VERSION ""

NS_ :

BS_:

BU_: ADAS

BO_ 3221225472 VECTOR__INDEPENDENT_SIG_MSG: 0 Vector__XXX
 SG_ AdsBcuExtAebCtlIfErr : 0|1@1+ (1,0) [0|1] "" Vector__XXX
 SG_ AdsBcuErr : 0|1@1+ (1,0) [0|1] "" Vector__XXX
 SG_ AdsAebHmiErr : 0|1@1+ (1,0) [0|1] "" Vector__XXX
 SG_ AdsSplyUErr : 0|1@1+ (1,0) [0|1] "" Vector__XXX
 SG_ AdsCurvErr : 0|1@1+ (1,0) [0|1] "" Vector__XXX
 SG_ AdsVLgtErr : 0|1@1+ (1,0) [0|1] "" Vector__XXX
 SG_ AdsHmiErr : 0|1@1+ (1,0) [0|1] "" Vector__XXX
 SG_ AdsAccrPedlPosnErr : 0|1@1+ (1,0) [0|1] "" Vector__XXX
 SG_ AdsGearPosnErr : 0|1@1+ (1,0) [0|1] "" Vector__XXX
 SG_ AdsAebErr : 0|1@1+ (1,0) [0|1] "" Vector__XXX
 SG_ AdsWhlSpdErr : 0|1@1+ (1,0) [0|1] "" Vector__XXX
 SG_ AdsYawRateErr : 0|1@1+ (1,0) [0|1] "" Vector__XXX
 SG_ AdsAccLatErr : 0|1@1+ (1,0) [0|1] "" Vector__XXX
 SG_ AdsAccLgtErr : 0|1@1+ (1,0) [0|1] "" Vector__XXX
 SG_ AdsBrkPedlPosnErr : 0|1@1+ (1,0) [0|1] "" Vector__XXX
 SG_ AdsRoadWhlAgErr : 0|1@1+ (1,0) [0|1] "" Vector__XXX
 SG_ AdsRadarErr : 0|1@1+ (1,0) [0|1] "" Vector__XXX
 SG_ AdsDriverTqReqErr : 0|1@1+ (1,0) [0|1] "" Vector__XXX
 SG_ AdsRadarBlkg : 0|1@1+ (1,0) [0|1] "" Vector__XXX

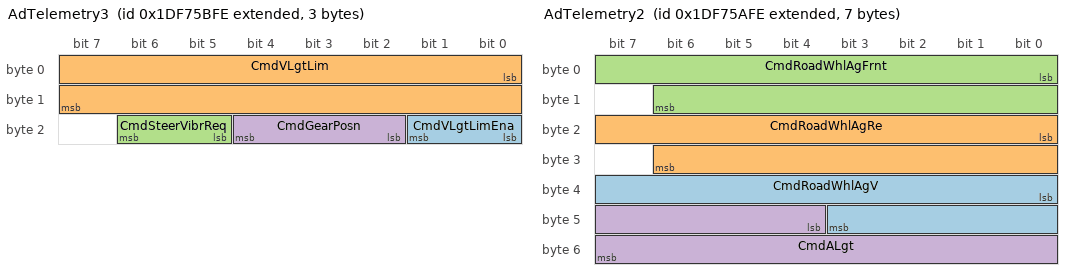
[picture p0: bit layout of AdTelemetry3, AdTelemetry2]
BO_ 2650233854 AdTelemetry3: 3 Vector__XXX
 SG_ CmdVLgtLimEna : 16|2@1+ (1,0) [0|3] "" Vector__XXX
 SG_ CmdVLgtLim : 0|16@1- (0.01,0) [-327.68|327.67] "m/s" Vector__XXX
 SG_ CmdSteerVibrReq : 21|2@1+ (1,0) [0|3] "" Vector__XXX
 SG_ CmdGearPosn : 18|3@1+ (1,0) [0|7] "" Vector__XXX

BO_ 2650233598 AdTelemetry2: 7 Vector__XXX
 SG_ CmdRoadWhlAgV : 32|12@1+ (0.01,0) [-20.48|20.47] "rad/s" Vector__XXX
 SG_ CmdRoadWhlAgRe : 16|15@1- (0.0001,0) [-1.6384|1.6383] "rad" Vector__XXX
 SG_ CmdRoadWhlAgFrnt : 0|15@1- (0.0001,0) [-1.6384|1.6383] "rad" Vector__XXX
 SG_ CmdALgt : 44|12@1- (0.01,0) [-20.48|20.47] "m/s^2" Vector__XXX

BO_ 2650233342 AdTelemetry1: 5 Vector__XXX
 SG_ CmdLgtExtReqPri : 30|2@1+ (1,0) [0|3] "" Vector__XXX
 SG_ CmdLgtExtReqMod : 27|3@1+ (1,0) [0|7] "" Vector__XXX
 SG_ CmdLatExtReqPri : 35|2@1+ (1,0) [0|3] "" Vector__XXX
 SG_ CmdLatExtReqMod : 32|3@1+ (1,0) [0|7] "" Vector__XXX
 SG_ AdSftyMod : 8|3@1+ (1,0) [0|7] "" Vector__XXX
 SG_ AdSteerTkvr : 4|1@1+ (1,0) [0|1] "" Vector__XXX
 SG_ AdSteerAcv : 1|1@1+ (1,0) [0|1] "" Vector__XXX
 SG_ AdSt : 11|3@1+ (1,0) [0|7] "" Vector__XXX
 SG_ AdHmiSt : 14|2@1+ (1,0) [0|3] "" Vector__XXX
 SG_ AdHmiEna : 16|3@1+ (1,0) [0|7] "" Vector__XXX
 SG_ AdDtTkvr : 5|1@1+ (1,0) [0|1] "" Vector__XXX
 SG_ AdDtAcv : 2|1@1+ (1,0) [0|1] "" Vector__XXX
 SG_ AdCtlMod : 19|3@1+ (1,0) [0|7] "" Vector__XXX
 SG_ AdCommSt : 22|2@1+ (1,0) [0|3] "" Vector__XXX
 SG_ AdCommEna : 24|3@1+ (1,0) [0|7] "" Vector__XXX
 SG_ AdBrkTkvr : 6|1@1+ (1,0) [0|1] "" Vector__XXX
 SG_ AdBrkAcv : 3|1@1+ (1,0) [0|1] "" Vector__XXX
 SG_ AdAcv : 0|1@1+ (1,0) [0|1] "" Vector__XXX

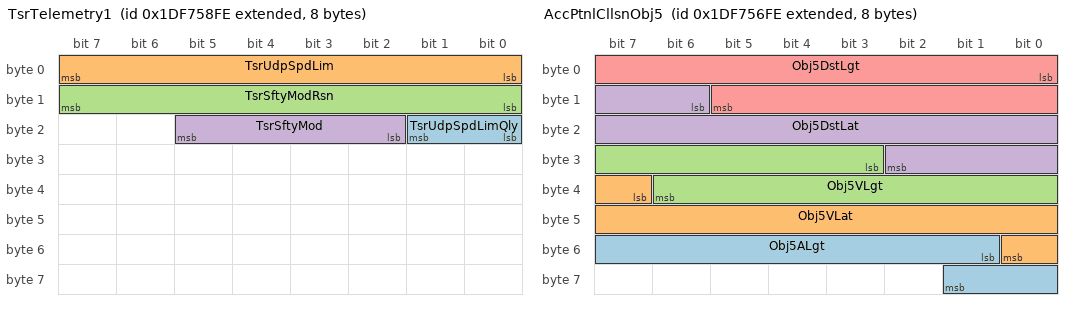
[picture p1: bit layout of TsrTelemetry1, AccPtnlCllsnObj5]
BO_ 2650233086 TsrTelemetry1: 8 Vector__XXX
 SG_ TsrUdpSpdLimQly : 16|2@1+ (1,0) [0|3] "" Vector__XXX
 SG_ TsrUdpSpdLim : 0|8@1+ (1,0) [0|255] "km/h" Vector__XXX
 SG_ TsrSftyModRsn : 8|8@1+ (1,0) [0|255] "" Vector__XXX
 SG_ TsrSftyMod : 18|4@1+ (1,0) [0|15] "" Vector__XXX

BO_ 2650232830 AebTelemetry2: 8 Vector__XXX
 SG_ AebSftyModRsn : 0|32@1+ (1,0) [0|4294967295] "" Vector__XXX

BO_ 2650232574 AccPtnlCllsnObj5: 8 Vector__XXX
 SG_ Obj5ALgt : 49|9@1+ (0.05,-12.8) [-12.8|12.75] "m/s^2" Vector__XXX
 SG_ Obj5VLat : 39|10@1+ (0.05,-25.6) [-25.6|25.55] "m/s" Vector__XXX
 SG_ Obj5VLgt : 27|12@1+ (0.05,-102.4) [-102.4|102.35] "m/s" Vector__XXX
 SG_ Obj5DstLat : 14|13@1+ (0.02,-81.92) [-81.92|81.9] "m" Vector__XXX
 SG_ Obj5DstLgt : 0|14@1+ (0.02,0) [0|327.66] "m" Vector__XXX

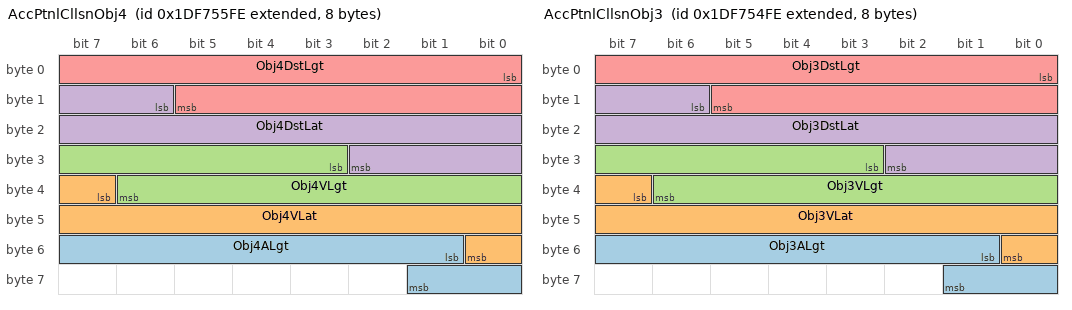
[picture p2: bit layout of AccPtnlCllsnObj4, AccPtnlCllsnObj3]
BO_ 2650232318 AccPtnlCllsnObj4: 8 Vector__XXX
 SG_ Obj4ALgt : 49|9@1+ (0.05,-12.8) [-12.8|12.75] "m/s^2" Vector__XXX
 SG_ Obj4VLat : 39|10@1+ (0.05,-25.6) [-25.6|25.55] "m/s" Vector__XXX
 SG_ Obj4VLgt : 27|12@1+ (0.05,-102.4) [-102.4|102.35] "m/s" Vector__XXX
 SG_ Obj4DstLat : 14|13@1+ (0.02,-81.92) [-81.92|81.9] "m" Vector__XXX
 SG_ Obj4DstLgt : 0|14@1+ (0.02,0) [0|327.66] "m" Vector__XXX

BO_ 2650232062 AccPtnlCllsnObj3: 8 Vector__XXX
 SG_ Obj3ALgt : 49|9@1+ (0.05,-12.8) [-12.8|12.75] "m/s^2" Vector__XXX
 SG_ Obj3VLat : 39|10@1+ (0.05,-25.6) [-25.6|25.55] "m/s" Vector__XXX
 SG_ Obj3VLgt : 27|12@1+ (0.05,-102.4) [-102.4|102.35] "m/s" Vector__XXX
 SG_ Obj3DstLat : 14|13@1+ (0.02,-81.92) [-81.92|81.9] "m" Vector__XXX
 SG_ Obj3DstLgt : 0|14@1+ (0.02,0) [0|327.66] "m" Vector__XXX

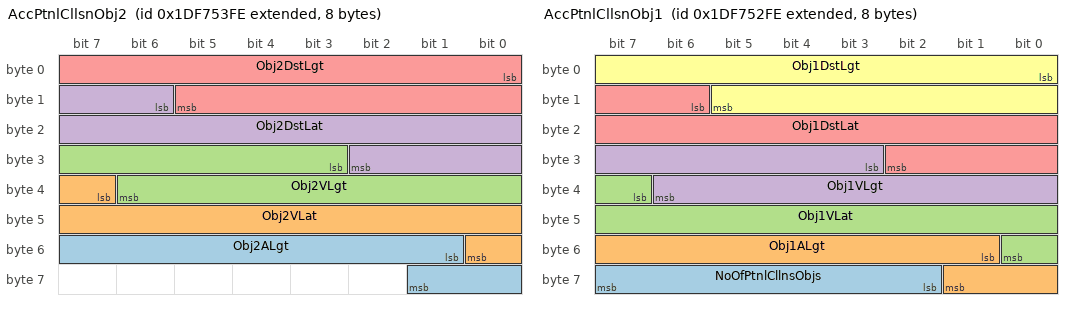
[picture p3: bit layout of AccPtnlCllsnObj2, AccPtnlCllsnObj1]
BO_ 2650231806 AccPtnlCllsnObj2: 8 Vector__XXX
 SG_ Obj2ALgt : 49|9@1+ (0.05,-12.8) [-12.8|12.75] "m/s^2" Vector__XXX
 SG_ Obj2VLat : 39|10@1+ (0.05,-25.6) [-25.6|25.55] "m/s" Vector__XXX
 SG_ Obj2VLgt : 27|12@1+ (0.05,-102.4) [-102.4|102.35] "m/s" Vector__XXX
 SG_ Obj2DstLat : 14|13@1+ (0.02,-81.92) [-81.92|81.9] "m" Vector__XXX
 SG_ Obj2DstLgt : 0|14@1+ (0.02,0) [0|327.66] "m" Vector__XXX

BO_ 2650231550 AccPtnlCllsnObj1: 8 Vector__XXX
 SG_ NoOfPtnlCllnsObjs : 58|6@1+ (1,0) [0|63] "" Vector__XXX
 SG_ Obj1ALgt : 49|9@1+ (0.05,-12.8) [-12.8|12.75] "m/s^2" Vector__XXX
 SG_ Obj1VLat : 39|10@1+ (0.05,-25.6) [-25.6|25.55] "m/s" Vector__XXX
 SG_ Obj1VLgt : 27|12@1+ (0.05,-102.4) [-102.4|102.35] "m/s" Vector__XXX
 SG_ Obj1DstLat : 14|13@1+ (0.02,-81.92) [-81.92|81.9] "m" Vector__XXX
 SG_ Obj1DstLgt : 0|14@1+ (0.02,0) [0|327.66] "m" Vector__XXX

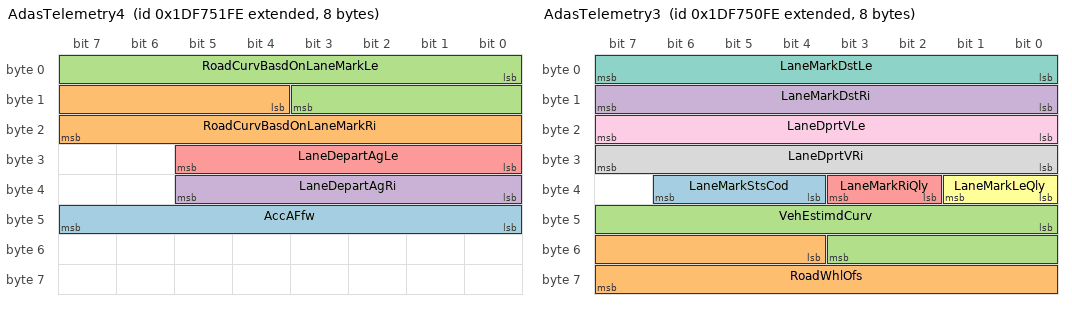
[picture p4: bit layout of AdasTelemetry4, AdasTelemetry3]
BO_ 2650231294 AdasTelemetry4: 8 Vector__XXX
 SG_ AccAFfw : 40|8@1+ (-0.01961,0) [-5.00055|0] "m/s^2" Vector__XXX
 SG_ RoadCurvBasdOnLaneMarkRi : 12|12@1+ (0.001,-2.048) [-2.048|2.047] "1/m" Vector__XXX
 SG_ RoadCurvBasdOnLaneMarkLe : 0|12@1+ (0.001,-2.048) [-2.048|2.047] "1/m" Vector__XXX
 SG_ LaneDepartAgRi : 32|6@1+ (0.01,-0.32) [-0.32|0.31] "rad" Vector__XXX
 SG_ LaneDepartAgLe : 24|6@1+ (0.01,-0.32) [-0.32|0.31] "rad" Vector__XXX

BO_ 2650231038 AdasTelemetry3: 8 Vector__XXX
 SG_ LaneMarkStsCod : 36|3@1+ (1,0) [0|7] "" Vector__XXX
 SG_ RoadWhlOfs : 52|12@1+ (1.7046E-005,-0.034901685) [-0.034901685|0.034901685] "rad" Vector__XXX
 SG_ VehEstimdCurv : 40|12@1+ (0.00048844,-1.0000809) [-1.0000809|1.0000809] "1/m" Vector__XXX
 SG_ LaneMarkDstRi : 8|8@1+ (0.02,0) [0|5.1] "m" Vector__XXX
 SG_ LaneMarkRiQly : 34|2@1+ (1,0) [0|3] "" Vector__XXX
 SG_ LaneMarkLeQly : 32|2@1+ (1,0) [0|3] "" Vector__XXX
 SG_ LaneMarkDstLe : 0|8@1+ (0.02,0) [0|5.1] "m" Vector__XXX
 SG_ LaneDprtVRi : 24|8@1+ (0.1,-12.8) [-12.8|12.7] "m/s" Vector__XXX
 SG_ LaneDprtVLe : 16|8@1+ (0.1,-12.8) [-12.8|12.7] "m/s" Vector__XXX

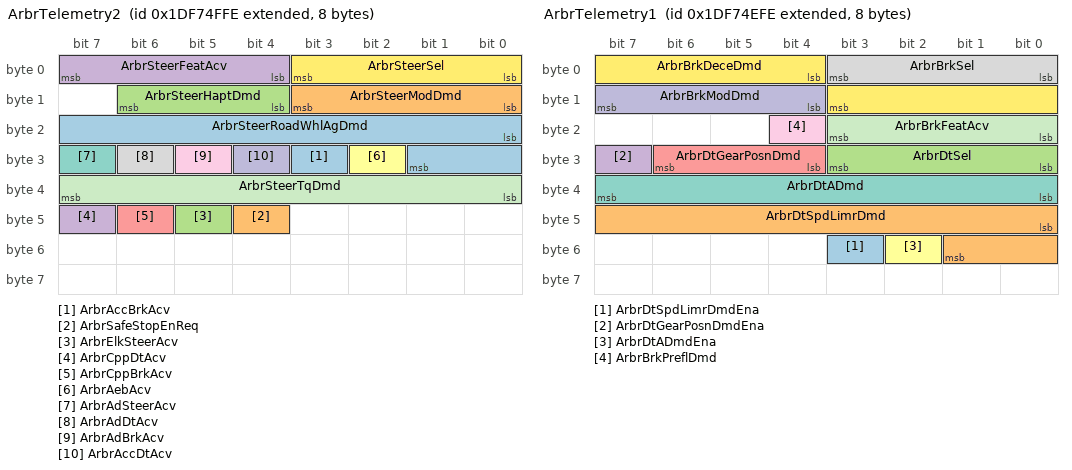
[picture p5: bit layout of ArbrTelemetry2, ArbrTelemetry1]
BO_ 2650230782 ArbrTelemetry2: 8 Vector__XXX
 SG_ ArbrAccBrkAcv : 27|1@1+ (1,0) [0|1] "" Vector__XXX
 SG_ ArbrSafeStopEnReq : 44|1@1+ (1,0) [0|1] "" Vector__XXX
 SG_ ArbrElkSteerAcv : 45|1@1+ (1,0) [0|1] "" Vector__XXX
 SG_ ArbrCppDtAcv : 47|1@1+ (1,0) [0|1] "" Vector__XXX
 SG_ ArbrCppBrkAcv : 46|1@1+ (1,0) [0|1] "" Vector__XXX
 SG_ ArbrAebAcv : 26|1@1+ (1,0) [0|1] "" Vector__XXX
 SG_ ArbrAdSteerAcv : 31|1@1+ (1,0) [0|1] "" Vector__XXX
 SG_ ArbrAdDtAcv : 30|1@1+ (1,0) [0|1] "" Vector__XXX
 SG_ ArbrAdBrkAcv : 29|1@1+ (1,0) [0|1] "" Vector__XXX
 SG_ ArbrAccDtAcv : 28|1@1+ (1,0) [0|1] "" Vector__XXX
 SG_ ArbrSteerTqDmd : 32|8@1+ (0.1,-12.8) [-12.8|12.7] "Nm" Vector__XXX
 SG_ ArbrSteerSel : 0|4@1+ (1,0) [0|15] "" Vector__XXX
 SG_ ArbrSteerRoadWhlAgDmd : 16|10@1+ (0.002,-1.024) [-1.024|1.022] "rad" Vector__XXX
 SG_ ArbrSteerModDmd : 8|4@1+ (1,0) [0|15] "" Vector__XXX
 SG_ ArbrSteerHaptDmd : 12|3@1+ (1,0) [0|7] "" Vector__XXX
 SG_ ArbrSteerFeatAcv : 4|4@1+ (1,0) [0|15] "" Vector__XXX

BO_ 2650230526 ArbrTelemetry1: 8 Vector__XXX
 SG_ ArbrDtSpdLimrDmdEna : 51|1@1+ (1,0) [0|1] "" Vector__XXX
 SG_ ArbrDtSpdLimrDmd : 40|10@1+ (0.05,0) [0|51.15] "m/s" Vector__XXX
 SG_ ArbrDtSel : 24|4@1+ (1,0) [0|15] "" Vector__XXX
 SG_ ArbrDtGearPosnDmdEna : 31|1@1+ (1,0) [0|1] "" Vector__XXX
 SG_ ArbrDtGearPosnDmd : 28|3@1+ (1,0) [0|7] "" Vector__XXX
 SG_ ArbrDtADmdEna : 50|1@1+ (1,0) [0|1] "" Vector__XXX
 SG_ ArbrDtADmd : 32|8@1+ (0.1,0) [0|25.5] "m/s^2" Vector__XXX
 SG_ ArbrBrkSel : 0|4@1+ (1,0) [0|15] "" Vector__XXX
 SG_ ArbrBrkPreflDmd : 20|1@1+ (1,0) [0|1] "" Vector__XXX
 SG_ ArbrBrkModDmd : 12|4@1+ (1,0) [0|15] "" Vector__XXX
 SG_ ArbrBrkFeatAcv : 16|4@1+ (1,0) [0|15] "" Vector__XXX
 SG_ ArbrBrkDeceDmd : 4|8@1+ (0.1,0) [0|25.5] "" Vector__XXX

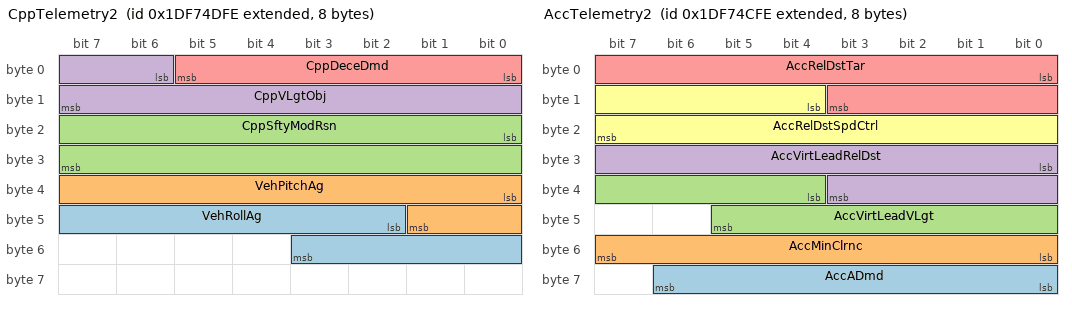
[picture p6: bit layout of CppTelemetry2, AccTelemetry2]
BO_ 2650230270 CppTelemetry2: 8 Vector__XXX
 SG_ VehRollAg : 42|10@1+ (0.05,-25.5) [-25.5|25.65] "deg" Vector__XXX
 SG_ VehPitchAg : 32|10@1+ (0.05,-25.5) [-25.5|25.65] "deg" Vector__XXX
 SG_ CppSftyModRsn : 16|16@1+ (1,0) [0|65535] "" Vector__XXX
 SG_ CppVLgtObj : 6|10@1+ (0.01,-5.12) [-5.12|5.11] "m/s" Vector__XXX
 SG_ CppDeceDmd : 0|6@1+ (0.1,0) [0|6.3] "m/s^2" Vector__XXX

BO_ 2650230014 AccTelemetry2: 8 Vector__XXX
 SG_ AccADmd : 56|7@1+ (0.1,-6.3) [-6.3|6.4] "m/s^2" Vector__XXX
 SG_ AccMinClrnc : 48|8@1+ (0.05,0) [0|12.75] "m" Vector__XXX
 SG_ AccVirtLeadVLgt : 36|10@1+ (0.05,0) [0|51.15] "m/s" Vector__XXX
 SG_ AccVirtLeadRelDst : 24|12@1+ (0.05,0) [0|204.75] "m" Vector__XXX
 SG_ AccRelDstTar : 0|12@1+ (0.05,0) [0|204.75] "m" Vector__XXX
 SG_ AccRelDstSpdCtrl : 12|12@1+ (0.05,0) [0|204.75] "m" Vector__XXX

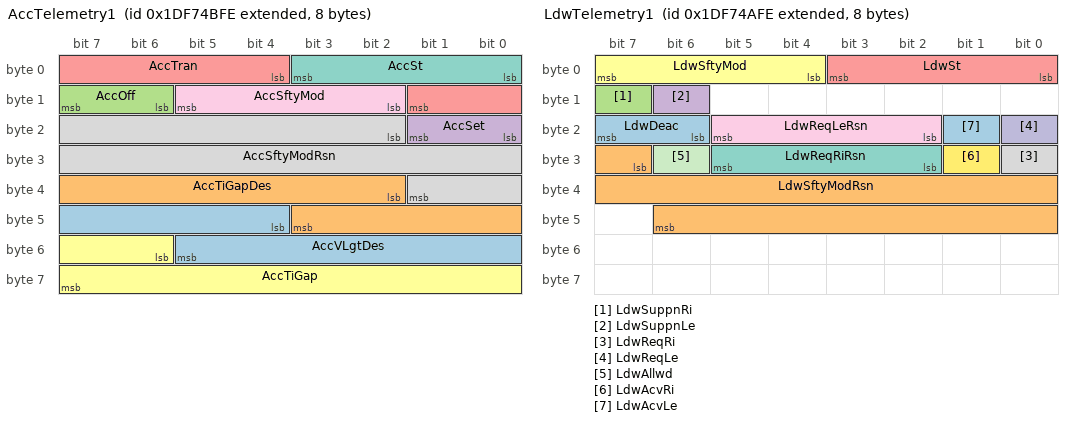
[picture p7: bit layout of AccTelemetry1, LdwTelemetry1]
BO_ 2650229758 AccTelemetry1: 8 Vector__XXX
 SG_ AccVLgtDes : 44|10@1+ (0.05,0) [0|51.15] "m/s" Vector__XXX
 SG_ AccTiGapDes : 34|10@1+ (0.01,0) [0|10.23] "s" Vector__XXX
 SG_ AccOff : 14|2@1+ (1,0) [0|3] "" Vector__XXX
 SG_ AccSet : 16|2@1+ (1,0) [0|3] "" Vector__XXX
 SG_ AccTran : 4|6@1+ (1,0) [0|63] "" Vector__XXX
 SG_ AccTiGap : 54|10@1+ (0.01,0) [0|10.23] "s" Vector__XXX
 SG_ AccSt : 0|4@1+ (1,0) [0|15] "" Vector__XXX
 SG_ AccSftyModRsn : 18|16@1+ (1,0) [0|65535] "" Vector__XXX
 SG_ AccSftyMod : 10|4@1+ (1,0) [0|15] "" Vector__XXX

BO_ 2650229502 LdwTelemetry1: 8 Vector__XXX
 SG_ LdwDeac : 22|2@1+ (1,0) [0|3] "" Vector__XXX
 SG_ LdwSftyModRsn : 31|16@1+ (1,0) [0|65535] "" Vector__XXX
 SG_ LdwSuppnRi : 15|1@1+ (1,0) [0|1] "" Vector__XXX
 SG_ LdwSuppnLe : 14|1@1+ (1,0) [0|1] "" Vector__XXX
 SG_ LdwSt : 0|4@1+ (1,0) [0|15] "" Vector__XXX
 SG_ LdwSftyMod : 4|4@1+ (1,0) [0|15] "" Vector__XXX
 SG_ LdwReqRiRsn : 26|4@1+ (1,0) [0|15] "" Vector__XXX
 SG_ LdwReqRi : 24|1@1+ (1,0) [0|1] "" Vector__XXX
 SG_ LdwReqLeRsn : 18|4@1+ (1,0) [0|15] "" Vector__XXX
 SG_ LdwReqLe : 16|1@1+ (1,0) [0|1] "" Vector__XXX
 SG_ LdwAllwd : 30|1@1+ (1,0) [0|1] "" Vector__XXX
 SG_ LdwAcvRi : 25|1@1+ (1,0) [0|1] "" Vector__XXX
 SG_ LdwAcvLe : 17|1@1+ (1,0) [0|1] "" Vector__XXX

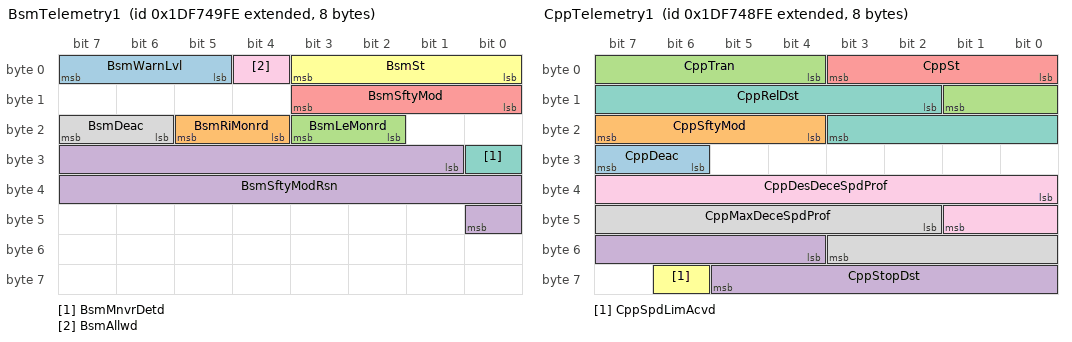
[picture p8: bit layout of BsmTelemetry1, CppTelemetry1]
BO_ 2650229246 BsmTelemetry1: 8 Vector__XXX
 SG_ BsmWarnLvl : 5|3@1+ (1,0) [0|7] "" Vector__XXX
 SG_ BsmRiMonrd : 20|2@1+ (1,0) [0|3] "" Vector__XXX
 SG_ BsmLeMonrd : 18|2@1+ (1,0) [0|3] "" Vector__XXX
 SG_ BsmSftyModRsn : 25|16@1+ (1,0) [0|65535] "" Vector__XXX
 SG_ BsmSftyMod : 8|4@1+ (1,0) [0|15] "" Vector__XXX
 SG_ BsmSt : 0|4@1+ (1,0) [0|15] "" Vector__XXX
 SG_ BsmMnvrDetd : 24|1@1+ (1,0) [0|1] "" Vector__XXX
 SG_ BsmDeac : 22|2@1+ (1,0) [0|3] "" Vector__XXX
 SG_ BsmAllwd : 4|1@1+ (1,0) [0|1] "" Vector__XXX

BO_ 2650228990 CppTelemetry1: 8 Vector__XXX
 SG_ CppDeac : 30|2@1+ (1,0) [0|3] "" Vector__XXX
 SG_ CppSftyMod : 20|4@1+ (1,0) [0|15] "" Vector__XXX
 SG_ CppTran : 4|6@1+ (1,0) [0|63] "" Vector__XXX
 SG_ CppStopDst : 52|10@1+ (0.01,-5.11) [-5.11|5.12] "m" Vector__XXX
 SG_ CppSt : 0|4@1+ (1,0) [0|15] "" Vector__XXX
 SG_ CppSpdLimAcvd : 62|1@1+ (1,0) [0|1] "" Vector__XXX
 SG_ CppRelDst : 10|10@1+ (0.01,-1) [-1|9.23] "m" Vector__XXX
 SG_ CppMaxDeceSpdProf : 42|10@1+ (0.01,0) [0|10.23] "m/s" Vector__XXX
 SG_ CppDesDeceSpdProf : 32|10@1+ (0.01,0) [0|10.23] "m/s" Vector__XXX

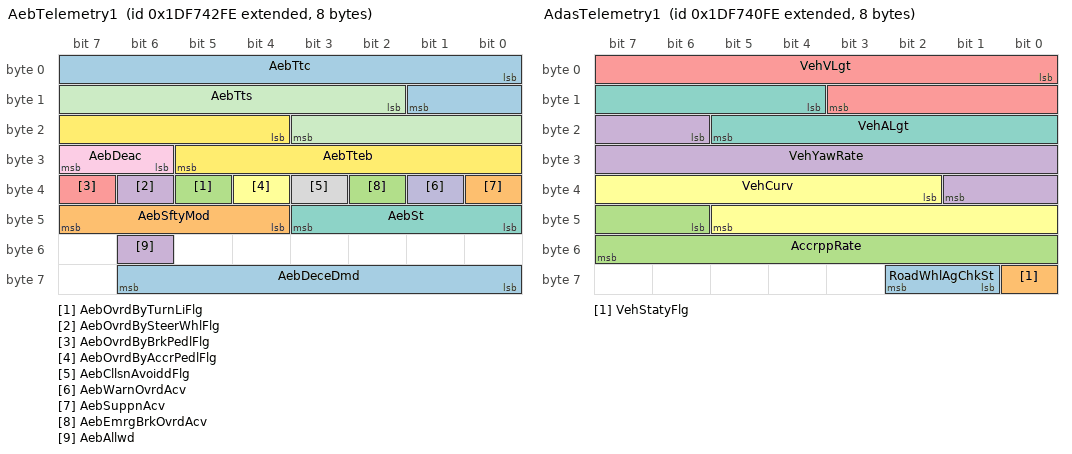
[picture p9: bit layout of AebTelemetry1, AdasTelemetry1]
BO_ 2650227454 AebTelemetry1: 8 Vector__XXX
 SG_ AebDeceDmd : 56|7@1+ (0.1,0) [0|12.7] "m/s^2" Vector__XXX
 SG_ AebSftyMod : 44|4@1+ (1,0) [0|15] "" Vector__XXX
 SG_ AebOvrdByTurnLiFlg : 37|1@1+ (1,0) [0|1] "" Vector__XXX
 SG_ AebOvrdBySteerWhlFlg : 38|1@1+ (1,0) [0|1] "" Vector__XXX
 SG_ AebOvrdByBrkPedlFlg : 39|1@1+ (1,0) [0|1] "" Vector__XXX
 SG_ AebOvrdByAccrPedlFlg : 36|1@1+ (1,0) [0|1] "" Vector__XXX
 SG_ AebSt : 40|4@1+ (1,0) [0|15] "" Vector__XXX
 SG_ AebCllsnAvoiddFlg : 35|1@1+ (1,0) [0|1] "" Vector__XXX
 SG_ AebDeac : 30|2@1+ (1,0) [0|3] "" Vector__XXX
 SG_ AebWarnOvrdAcv : 33|1@1+ (1,0) [0|1] "" Vector__XXX
 SG_ AebTts : 10|10@1+ (0.01,0) [0|10.23] "s" Vector__XXX
 SG_ AebTteb : 20|10@1+ (0.01,0) [0|10.23] "s" Vector__XXX
 SG_ AebTtc : 0|10@1+ (0.01,0) [0|10.23] "s" Vector__XXX
 SG_ AebSuppnAcv : 32|1@1+ (1,0) [0|1] "" Vector__XXX
 SG_ AebEmrgBrkOvrdAcv : 34|1@1+ (1,0) [0|1] "" Vector__XXX
 SG_ AebAllwd : 54|1@1+ (1,0) [0|1] "" Vector__XXX

BO_ 2650226942 AdasTelemetry1: 8 Vector__XXX
 SG_ RoadWhlAgChkSt : 57|2@1+ (1,0) [0|3] "" Vector__XXX
 SG_ VehStatyFlg : 56|1@1+ (1,0) [0|1] "" Vector__XXX
 SG_ AccrppRate : 46|10@1+ (2,-1024) [-1024|1022] "%/s" Vector__XXX
 SG_ VehYawRate : 22|12@1+ (0.001,-2.048) [-2.048|2.047] "rad/s" Vector__XXX
 SG_ VehVLgt : 0|12@1+ (0.05,-102.4) [-102.4|102.35] "m/s" Vector__XXX
 SG_ VehCurv : 34|12@1+ (0.00048844,-1.0000809) [-1.0000809|1.0000809] "1/m" Vector__XXX
 SG_ VehALgt : 12|10@1+ (0.05,-25.6) [-25.6|25.55] "m/s^2" Vector__XXX

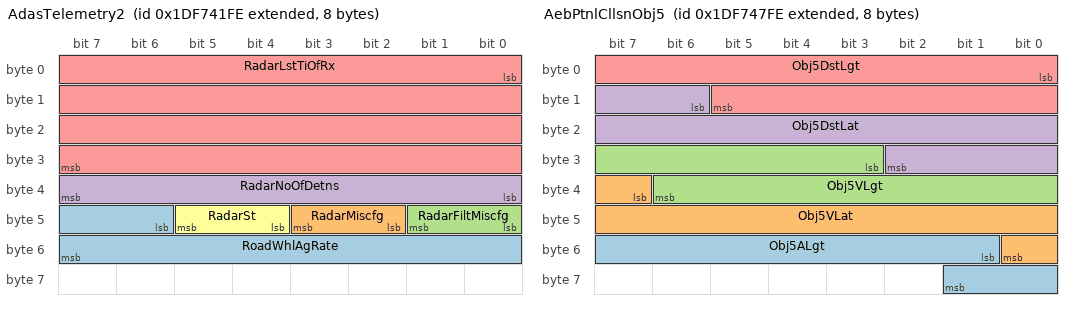
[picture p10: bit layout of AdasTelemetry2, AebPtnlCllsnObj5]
BO_ 2650227198 AdasTelemetry2: 8 Vector__XXX
 SG_ RoadWhlAgRate : 46|10@1+ (0.05,-25.6) [-25.6|25.55] "rad/s" Vector__XXX
 SG_ RadarMiscfg : 42|2@1+ (1,0) [0|3] "" Vector__XXX
 SG_ RadarFiltMiscfg : 40|2@1+ (1,0) [0|3] "" Vector__XXX
 SG_ RadarNoOfDetns : 32|8@1+ (1,0) [0|255] "" Vector__XXX
 SG_ RadarLstTiOfRx : 0|32@1+ (1,0) [0|4294967295] "" Vector__XXX
 SG_ RadarSt : 44|2@1+ (1,0) [0|3] "" Vector__XXX

BO_ 2650228734 AebPtnlCllsnObj5: 8 Vector__XXX
 SG_ Obj5ALgt : 49|9@1+ (0.05,-12.8) [-12.8|12.75] "m/s^2" Vector__XXX
 SG_ Obj5VLat : 39|10@1+ (0.05,-25.6) [-25.6|25.55] "m/s" Vector__XXX
 SG_ Obj5VLgt : 27|12@1+ (0.05,-102.4) [-102.4|102.35] "m/s" Vector__XXX
 SG_ Obj5DstLat : 14|13@1+ (0.02,-81.92) [-81.92|81.9] "m" Vector__XXX
 SG_ Obj5DstLgt : 0|14@1+ (0.02,0) [0|327.66] "m" Vector__XXX

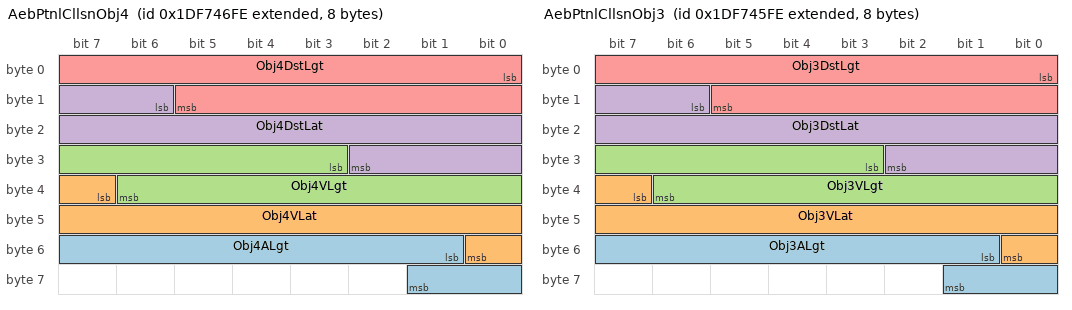
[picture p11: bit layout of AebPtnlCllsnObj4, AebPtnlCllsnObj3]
BO_ 2650228478 AebPtnlCllsnObj4: 8 Vector__XXX
 SG_ Obj4ALgt : 49|9@1+ (0.05,-12.8) [-12.8|12.75] "m/s^2" Vector__XXX
 SG_ Obj4VLat : 39|10@1+ (0.05,-25.6) [-25.6|25.55] "m/s" Vector__XXX
 SG_ Obj4VLgt : 27|12@1+ (0.05,-102.4) [-102.4|102.35] "m/s" Vector__XXX
 SG_ Obj4DstLat : 14|13@1+ (0.02,-81.92) [-81.92|81.9] "m" Vector__XXX
 SG_ Obj4DstLgt : 0|14@1+ (0.02,0) [0|327.66] "m" Vector__XXX

BO_ 2650228222 AebPtnlCllsnObj3: 8 Vector__XXX
 SG_ Obj3ALgt : 49|9@1+ (0.05,-12.8) [-12.8|12.75] "m/s^2" Vector__XXX
 SG_ Obj3VLat : 39|10@1+ (0.05,-25.6) [-25.6|25.55] "m/s" Vector__XXX
 SG_ Obj3VLgt : 27|12@1+ (0.05,-102.4) [-102.4|102.35] "m/s" Vector__XXX
 SG_ Obj3DstLat : 14|13@1+ (0.02,-81.92) [-81.92|81.9] "m" Vector__XXX
 SG_ Obj3DstLgt : 0|14@1+ (0.02,0) [0|327.66] "m" Vector__XXX

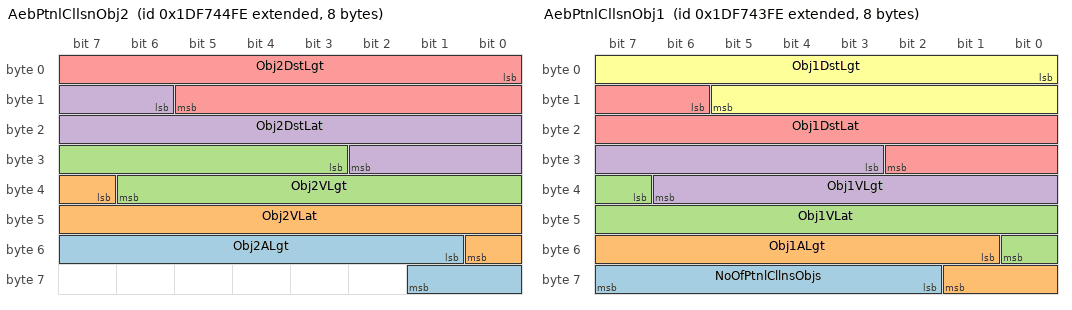
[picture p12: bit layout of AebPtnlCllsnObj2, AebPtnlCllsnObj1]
BO_ 2650227966 AebPtnlCllsnObj2: 8 Vector__XXX
 SG_ Obj2ALgt : 49|9@1+ (0.05,-12.8) [-12.8|12.75] "m/s^2" Vector__XXX
 SG_ Obj2VLat : 39|10@1+ (0.05,-25.6) [-25.6|25.55] "m/s" Vector__XXX
 SG_ Obj2VLgt : 27|12@1+ (0.05,-102.4) [-102.4|102.35] "m/s" Vector__XXX
 SG_ Obj2DstLat : 14|13@1+ (0.02,-81.92) [-81.92|81.9] "m" Vector__XXX
 SG_ Obj2DstLgt : 0|14@1+ (0.02,0) [0|327.66] "m" Vector__XXX

BO_ 2650227710 AebPtnlCllsnObj1: 8 Vector__XXX
 SG_ NoOfPtnlCllnsObjs : 58|6@1+ (1,0) [0|63] "" Vector__XXX
 SG_ Obj1ALgt : 49|9@1+ (0.05,-12.8) [-12.8|12.75] "m/s^2" Vector__XXX
 SG_ Obj1VLat : 39|10@1+ (0.05,-25.6) [-25.6|25.55] "m/s" Vector__XXX
 SG_ Obj1VLgt : 27|12@1+ (0.05,-102.4) [-102.4|102.35] "m/s" Vector__XXX
 SG_ Obj1DstLat : 14|13@1+ (0.02,-81.92) [-81.92|81.9] "m" Vector__XXX
 SG_ Obj1DstLgt : 0|14@1+ (0.02,0) [0|327.66] "m" Vector__XXX

CM_ BO_ 3221225472 "This is a message for not used signals, created by Vector CANdb++ DBC OLE DB Provider.";
CM_ SG_ 3221225472 AdsBcuExtAebCtlIfErr "Braking system AEB control interface error";
CM_ SG_ 3221225472 AdsBcuErr "Braking system error";
CM_ SG_ 3221225472 AdsAebHmiErr "AEB-HMI system error";
CM_ SG_ 3221225472 AdsSplyUErr "Supply voltage error";
CM_ SG_ 3221225472 AdsCurvErr "Curvature quality error";
CM_ SG_ 3221225472 AdsVLgtErr "Longitudinal velocity quality error";
CM_ SG_ 3221225472 AdsHmiErr "HMI system error";
CM_ SG_ 3221225472 AdsAccrPedlPosnErr "Accelerator pedal position quality error";
CM_ SG_ 3221225472 AdsGearPosnErr "Gear position quality error";
CM_ SG_ 3221225472 AdsAebErr "AEB system error";
CM_ SG_ 3221225472 AdsWhlSpdErr "Wheel speeds quality error";
CM_ SG_ 3221225472 AdsYawRateErr "Yaw Rate quality error";
CM_ SG_ 3221225472 AdsAccLatErr "Lateral acceleration quality error";
CM_ SG_ 3221225472 AdsAccLgtErr "Longitudinal acceleration quality error";
CM_ SG_ 3221225472 AdsBrkPedlPosnErr "Brake pedal position quality error";
CM_ SG_ 3221225472 AdsRoadWhlAgErr "Road wheel angle quality error";
CM_ SG_ 3221225472 AdsRadarErr "Radar general error";
CM_ SG_ 3221225472 AdsDriverTqReqErr "Driver steering torque request quality error";
CM_ SG_ 3221225472 AdsRadarBlkg "Radar Blockage error";
CM_ SG_ 2650233342 AdSftyMod "AD safety flag from AD Controller in ADAS";
CM_ SG_ 2650233342 AdSteerAcv "AD steering activation flag from AD Controller in ADAS";
CM_ SG_ 2650233342 AdDtAcv "AD drivetrain activation flag from AD Controller in ADAS";
CM_ SG_ 2650233342 AdBrkAcv "AD braking activation flag from AD Controller in ADAS";
CM_ SG_ 2650233342 AdAcv "Combined AD activation flag from AD controller in ADAS";
CM_ BO_ 2650233086 "TSR Telemetry message 1";
CM_ SG_ 2650233086 TsrUdpSpdLimQly "Quality of the current speed limit sended to TSR manager from UDP";
CM_ SG_ 2650233086 TsrUdpSpdLim "Current speed limit sended to TSR manager from UDP";
CM_ SG_ 2650233086 TsrSftyModRsn "Reason number for safety error mode";
CM_ SG_ 2650233086 TsrSftyMod "Safety error mode";
CM_ BO_ 2650232830 "AEB Telemetry message 2";
CM_ SG_ 2650232830 AebSftyModRsn "Reason bit mask for safety error mode";
CM_ SG_ 2650231550 NoOfPtnlCllnsObjs "Number of potential collision objects";
CM_ BO_ 2650231294 "LDW Telemetry message 1";
CM_ SG_ 2650231294 AccAFfw "Acc feedforward deceleration component m/s^2";
CM_ SG_ 2650231294 RoadCurvBasdOnLaneMarkRi "Road Curvature Based on Right Lane Marks";
CM_ SG_ 2650231294 RoadCurvBasdOnLaneMarkLe "Road Curvature Based on Left Lane Marks";
CM_ SG_ 2650231294 LaneDepartAgRi "Angle between right lane mark and vehicle driving direction.";
CM_ SG_ 2650231294 LaneDepartAgLe "Angle between left lane mark and vehicle driving direction.";
CM_ BO_ 2650231038 "LDW Telemetry message 1";
CM_ SG_ 2650231038 LaneMarkStsCod "Lane detection pipeline status code.

000b = ok
001b = not available
010b = hardware failure
011b = camera obstruction
100b to 111b = reserved for future";
CM_ SG_ 2650231038 RoadWhlOfs "Ego vehicle estimated current path cuvature";
CM_ SG_ 2650231038 VehEstimdCurv "Ego vehicle estimated current path cuvature";
CM_ SG_ 2650231038 LaneMarkDstRi "Right Distance to Lane Mark from Vehicle's Middle";
CM_ SG_ 2650231038 LaneMarkRiQly "Lane Mark Quality on the Right Side";
CM_ SG_ 2650231038 LaneMarkLeQly "Lane Mark Quality on the Left Side";
CM_ SG_ 2650231038 LaneMarkDstLe "Left Distance to Lane Mark from Vehicle's Middle";
CM_ SG_ 2650231038 LaneDprtVRi "Right lane departure velocity. 
The velocity is positive while vehicle is moving towards the lane marks, and negative if not.";
CM_ SG_ 2650231038 LaneDprtVLe "Left lane departure velocity. 
The velocity is positive while vehicle is moving towards the lane marks, and negative if not.";
CM_ BO_ 2650230782 "Supervisor Telemetry message 2";
CM_ SG_ 2650230782 ArbrAccBrkAcv "ACC braking activation flag for Arbitrator";
CM_ SG_ 2650230782 ArbrSafeStopEnReq "SafeStop activation flag for Arbitrator from AD controller";
CM_ SG_ 2650230782 ArbrElkSteerAcv "ELK steering activation flag for Arbitrator";
CM_ SG_ 2650230782 ArbrCppDtAcv "Cpp drivetrain activation flag for Arbitrator";
CM_ SG_ 2650230782 ArbrCppBrkAcv "CPP braking activation flag for Arbitrator";
CM_ SG_ 2650230782 ArbrAebAcv "AEB braking activation flag for Arbitrator";
CM_ SG_ 2650230782 ArbrAdSteerAcv "AD steering activation flag from AD Controller";
CM_ SG_ 2650230782 ArbrAdDtAcv "AD drievtrain activation flag from AD Controller";
CM_ SG_ 2650230782 ArbrAdBrkAcv "AD braking activation flag from AD Controller";
CM_ SG_ 2650230782 ArbrAccDtAcv "ACC drivetrain activation flag for Arbitrator";
CM_ BO_ 2650230526 "Supervisor Telemetry message 1";
CM_ BO_ 2650230270 "CPP Telemetry message 2";
CM_ SG_ 2650230270 CppSftyModRsn "Reason number for safety error mode";
CM_ BO_ 2650230014 "ACC Telemetry message 2";
CM_ BO_ 2650229758 "ACC Telemetry message 1";
CM_ SG_ 2650229758 AccOff "AEB deactivation request state";
CM_ SG_ 2650229758 AccSet "AEB Set request state";
CM_ SG_ 2650229758 AccTran "ACC Statemachine transition reason";
CM_ SG_ 2650229758 AccSt "ACC State";
CM_ SG_ 2650229758 AccSftyModRsn "Reason number for safety error mode";
CM_ SG_ 2650229758 AccSftyMod "Safety error mode";
CM_ BO_ 2650229502 "LDW Telemetry message 1";
CM_ SG_ 2650229502 LdwSftyModRsn "Reason number for safety error mode";
CM_ SG_ 2650229502 LdwSuppnRi "Right lane departure warning suppression";
CM_ SG_ 2650229502 LdwSuppnLe "Left lane departure warning suppression";
CM_ SG_ 2650229502 LdwSt "LDW State";
CM_ SG_ 2650229502 LdwSftyMod "Safety error mode";
CM_ SG_ 2650229502 LdwReqRiRsn "Transition reason for LdwReqRi";
CM_ SG_ 2650229502 LdwReqRi "Right lane departure warning request";
CM_ SG_ 2650229502 LdwReqLeRsn "Transition reason for LdwReqLe";
CM_ SG_ 2650229502 LdwReqLe "Left lane departure warning request";
CM_ SG_ 2650229502 LdwAllwd "LDW is allowed";
CM_ SG_ 2650229502 LdwAcvRi "Right lane departure warning is active";
CM_ SG_ 2650229502 LdwAcvLe "Left lane departure warning is active";
CM_ BO_ 2650229246 "BSM Telemetry message 1";
CM_ SG_ 2650229246 BsmSftyModRsn "Reason number for safety error mode";
CM_ SG_ 2650229246 BsmSftyMod "Safety error mode";
CM_ SG_ 2650229246 BsmSt "BSM State";
CM_ SG_ 2650229246 BsmMnvrDetd "BSM maneuver detected";
CM_ SG_ 2650229246 BsmDeac "BSM deactivation request state";
CM_ SG_ 2650229246 BsmAllwd "BSM is allowed";
CM_ BO_ 2650228990 "CPP Telemetry message 1";
CM_ SG_ 2650228990 CppSftyMod "Safety error mode";
CM_ SG_ 2650228990 CppTran "CPP Statemachine transition reason";
CM_ SG_ 2650228990 CppStopDst "CPP Distance where vehicle will be stopped with maximum deceleration";
CM_ SG_ 2650228990 CppSt "CPP State";
CM_ SG_ 2650228990 CppSpdLimAcvd "CPP Command to activate speed limit. True - enable, false - disable";
CM_ SG_ 2650228990 CppRelDst "CPP Relative distance to an object";
CM_ SG_ 2650228990 CppMaxDeceSpdProf "CPP Speed profile calculated based on maximum available deceleration requiest";
CM_ SG_ 2650228990 CppDesDeceSpdProf "CPP Speed profile calculated based on target deceleration";
CM_ BO_ 2650227454 "AEB Telemetry message 1";
CM_ SG_ 2650227454 AebSftyMod "Safety error mode";
CM_ SG_ 2650227454 AebOvrdByTurnLiFlg "Suppression or override by turn light is active";
CM_ SG_ 2650227454 AebOvrdBySteerWhlFlg "Suppression or override by steering wheel is active";
CM_ SG_ 2650227454 AebOvrdByBrkPedlFlg "Suppression or override by braking pedal is active";
CM_ SG_ 2650227454 AebOvrdByAccrPedlFlg "Suppression or override by accelerator pedal is active";
CM_ SG_ 2650227454 AebSt "AEB State";
CM_ SG_ 2650227454 AebCllsnAvoiddFlg "Is collision avoided flag";
CM_ SG_ 2650227454 AebDeac "AEB deactivation request state";
CM_ SG_ 2650227454 AebWarnOvrdAcv "Override of AEB Warning phase is active";
CM_ SG_ 2650227454 AebTts "Time to stop estimation";
CM_ SG_ 2650227454 AebTteb "Time to emergency braking estimation";
CM_ SG_ 2650227454 AebTtc "Time to collision estimation";
CM_ SG_ 2650227454 AebSuppnAcv "Suppression of AEB is active";
CM_ SG_ 2650227454 AebEmrgBrkOvrdAcv "Override of AEB EB phase is active";
CM_ SG_ 2650227454 AebAllwd "AEB is allowed";
CM_ BO_ 2650226942 "ADAS Telemetry message 1";
CM_ SG_ 2650226942 RoadWhlAgChkSt "Road wheel angle sensor check state";
CM_ SG_ 2650226942 VehStatyFlg "Flag indicating is SV stationary";
CM_ SG_ 2650226942 AccrppRate "Current rate (velocity) of accelerator pedal position";
CM_ SG_ 2650226942 VehCurv "Ego vehicle estimated current path cuvature";
CM_ BO_ 2650227198 "ADAS Telemetry message 2";
CM_ SG_ 2650227198 RoadWhlAgRate "Current rate (velocity) of road wheel angle";
CM_ SG_ 2650227198 RadarNoOfDetns "Radar number of detections";
CM_ SG_ 2650227198 RadarLstTiOfRx "Last time sample of detections data receive";
CM_ SG_ 2650227198 RadarSt "Radar state";
CM_ SG_ 2650227710 NoOfPtnlCllnsObjs "Number of potential collision objects";
BA_DEF_ SG_  "SigType" ENUM  "Default","Range","RangeSigned","ASCII","Discrete","Control","ReferencePGN","DTC","StringDelimiter","StringLength","StringLengthControl","MessageCounter","MessageChecksum";
BA_DEF_ SG_  "GenSigEVName" STRING ;
BA_DEF_ SG_  "GenSigILSupport" ENUM  "No","Yes";
BA_DEF_ SG_  "GenSigSendType" ENUM  "Cyclic","OnWrite","OnWriteWithRepetition","OnChange","OnChangeWithRepetition","IfActive","IfActiveWithRepetition","NoSigSendType";
BA_DEF_ SG_  "GenSigStartValue" INT 0 2147483647;
BA_DEF_ BO_  "GenMsgILSupport" ENUM  "No","Yes";
BA_DEF_ BU_  "NmStationAddress" INT 0 255;
BA_DEF_ BO_  "GenMsgSendType" ENUM  "cyclic","NotUsed","IfActive","NotUsed","NotUsed","NotUsed","NotUsed","NotUsed","noMsgSendType";
BA_DEF_ BO_  "GenMsgRequestable" INT 0 1;
BA_DEF_ BO_  "GenMsgCycleTime" INT 0 3600000;
BA_DEF_ SG_  "SPN" INT 0 524287;
BA_DEF_  "DBName" STRING ;
BA_DEF_  "BusType" STRING ;
BA_DEF_  "ProtocolType" STRING ;
BA_DEF_ BO_  "VFrameFormat" ENUM  "StandardCAN","ExtendedCAN","reserved","J1939PG";
BA_DEF_DEF_  "SigType" "Default";
BA_DEF_DEF_  "GenSigEVName" "Env@Nodename_@Signame";
BA_DEF_DEF_  "GenSigILSupport" "Yes";
BA_DEF_DEF_  "GenSigSendType" "NoSigSendType";
BA_DEF_DEF_  "GenSigStartValue" 0;
BA_DEF_DEF_  "GenMsgILSupport" "Yes";
BA_DEF_DEF_  "NmStationAddress" 254;
BA_DEF_DEF_  "GenMsgSendType" "noMsgSendType";
BA_DEF_DEF_  "GenMsgRequestable" 1;
BA_DEF_DEF_  "GenMsgCycleTime" 0;
BA_DEF_DEF_  "SPN" 0;
BA_DEF_DEF_  "DBName" "";
BA_DEF_DEF_  "BusType" "CAN";
BA_DEF_DEF_  "ProtocolType" "J1939";
BA_DEF_DEF_  "VFrameFormat" "J1939PG";
BA_ "DBName" "ADAS_Telemetry";
BA_ "NmStationAddress" BU_ ADAS 17;
BA_ "GenMsgCycleTime" BO_ 2650233854 10;
BA_ "GenMsgCycleTime" BO_ 2650233598 10;
BA_ "GenMsgCycleTime" BO_ 2650233342 10;
BA_ "GenMsgCycleTime" BO_ 2650233086 10;
BA_ "GenMsgCycleTime" BO_ 2650232830 100;
BA_ "GenMsgCycleTime" BO_ 2650232574 70;
BA_ "GenMsgCycleTime" BO_ 2650232318 70;
BA_ "GenMsgCycleTime" BO_ 2650232062 70;
BA_ "GenMsgCycleTime" BO_ 2650231806 70;
BA_ "GenMsgCycleTime" BO_ 2650231550 70;
BA_ "GenMsgCycleTime" BO_ 2650231294 10;
BA_ "GenMsgCycleTime" BO_ 2650231038 10;
BA_ "GenMsgCycleTime" BO_ 2650230782 10;
BA_ "GenMsgCycleTime" BO_ 2650230526 10;
BA_ "GenMsgCycleTime" BO_ 2650230270 10;
BA_ "GenMsgCycleTime" BO_ 2650230014 10;
BA_ "GenMsgCycleTime" BO_ 2650229758 10;
BA_ "GenMsgCycleTime" BO_ 2650229502 10;
BA_ "GenMsgCycleTime" BO_ 2650229246 10;
BA_ "GenMsgCycleTime" BO_ 2650228990 10;
BA_ "GenMsgCycleTime" BO_ 2650227454 10;
BA_ "GenMsgCycleTime" BO_ 2650226942 10;
BA_ "GenMsgCycleTime" BO_ 2650227198 10;
BA_ "GenMsgCycleTime" BO_ 2650228734 70;
BA_ "GenMsgCycleTime" BO_ 2650228478 70;
BA_ "GenMsgCycleTime" BO_ 2650228222 70;
BA_ "GenMsgCycleTime" BO_ 2650227966 70;
BA_ "GenMsgCycleTime" BO_ 2650227710 70;
BA_ "SPN" SG_ 3221225472 AdsBcuExtAebCtlIfErr 519718;
BA_ "SPN" SG_ 3221225472 AdsBcuErr 519717;
BA_ "SPN" SG_ 3221225472 AdsAebHmiErr 519716;
BA_ "SPN" SG_ 3221225472 AdsSplyUErr 519715;
BA_ "SPN" SG_ 3221225472 AdsCurvErr 519714;
BA_ "SPN" SG_ 3221225472 AdsVLgtErr 519713;
BA_ "SPN" SG_ 3221225472 AdsHmiErr 519712;
BA_ "SPN" SG_ 3221225472 AdsAccrPedlPosnErr 519711;
BA_ "SPN" SG_ 3221225472 AdsGearPosnErr 519710;
BA_ "SPN" SG_ 3221225472 AdsAebErr 519709;
BA_ "SPN" SG_ 3221225472 AdsWhlSpdErr 519708;
BA_ "SPN" SG_ 3221225472 AdsYawRateErr 519707;
BA_ "SPN" SG_ 3221225472 AdsAccLatErr 519706;
BA_ "SPN" SG_ 3221225472 AdsAccLgtErr 519705;
BA_ "SPN" SG_ 3221225472 AdsBrkPedlPosnErr 519704;
BA_ "SPN" SG_ 3221225472 AdsRoadWhlAgErr 519703;
BA_ "SPN" SG_ 3221225472 AdsRadarErr 519701;
BA_ "SPN" SG_ 3221225472 AdsDriverTqReqErr 519702;
BA_ "SPN" SG_ 3221225472 AdsRadarBlkg 519700;
BA_ "GenSigStartValue" SG_ 2650232574 Obj5ALgt 256;
BA_ "GenSigStartValue" SG_ 2650232574 Obj5VLat 512;
BA_ "GenSigStartValue" SG_ 2650232574 Obj5VLgt 2048;
BA_ "GenSigStartValue" SG_ 2650232574 Obj5DstLat 4096;
BA_ "GenSigStartValue" SG_ 2650232318 Obj4ALgt 256;
BA_ "GenSigStartValue" SG_ 2650232318 Obj4VLat 512;
BA_ "GenSigStartValue" SG_ 2650232318 Obj4VLgt 2048;
BA_ "GenSigStartValue" SG_ 2650232318 Obj4DstLat 4096;
BA_ "GenSigStartValue" SG_ 2650232062 Obj3ALgt 256;
BA_ "GenSigStartValue" SG_ 2650232062 Obj3VLat 512;
BA_ "GenSigStartValue" SG_ 2650232062 Obj3VLgt 2048;
BA_ "GenSigStartValue" SG_ 2650232062 Obj3DstLat 4096;
BA_ "GenSigStartValue" SG_ 2650231806 Obj2ALgt 256;
BA_ "GenSigStartValue" SG_ 2650231806 Obj2VLat 512;
BA_ "GenSigStartValue" SG_ 2650231806 Obj2VLgt 2048;
BA_ "GenSigStartValue" SG_ 2650231806 Obj2DstLat 4096;
BA_ "GenSigStartValue" SG_ 2650231550 Obj1ALgt 256;
BA_ "GenSigStartValue" SG_ 2650231550 Obj1VLat 512;
BA_ "GenSigStartValue" SG_ 2650231550 Obj1VLgt 2048;
BA_ "GenSigStartValue" SG_ 2650231550 Obj1DstLat 4096;
BA_ "GenSigStartValue" SG_ 2650231294 RoadCurvBasdOnLaneMarkRi 2048;
BA_ "GenSigStartValue" SG_ 2650231294 RoadCurvBasdOnLaneMarkLe 2048;
BA_ "GenSigStartValue" SG_ 2650231294 LaneDepartAgRi 32;
BA_ "GenSigStartValue" SG_ 2650231294 LaneDepartAgLe 32;
BA_ "GenSigStartValue" SG_ 2650231038 RoadWhlOfs 2047.5;
BA_ "GenSigStartValue" SG_ 2650231038 VehEstimdCurv 2047.5;
BA_ "GenSigStartValue" SG_ 2650231038 LaneDprtVRi 128;
BA_ "GenSigStartValue" SG_ 2650231038 LaneDprtVLe 128;
BA_ "GenSigStartValue" SG_ 2650230782 ArbrSteerTqDmd 128;
BA_ "GenSigStartValue" SG_ 2650230782 ArbrSteerRoadWhlAgDmd 512;
BA_ "GenSigStartValue" SG_ 2650230270 VehRollAg 510;
BA_ "GenSigStartValue" SG_ 2650230270 VehPitchAg 510;
BA_ "GenSigStartValue" SG_ 2650230270 CppVLgtObj 512;
BA_ "GenSigStartValue" SG_ 2650230014 AccADmd 63;
BA_ "GenSigStartValue" SG_ 2650228990 CppStopDst 511;
BA_ "GenSigStartValue" SG_ 2650228990 CppRelDst 100;
BA_ "GenSigStartValue" SG_ 2650226942 AccrppRate 512;
BA_ "GenSigStartValue" SG_ 2650226942 VehYawRate 2048;
BA_ "GenSigStartValue" SG_ 2650226942 VehVLgt 2048;
BA_ "GenSigStartValue" SG_ 2650226942 VehCurv 2047.5;
BA_ "GenSigStartValue" SG_ 2650226942 VehALgt 512;
BA_ "GenSigStartValue" SG_ 2650227198 RoadWhlAgRate 512;
BA_ "GenSigStartValue" SG_ 2650228734 Obj5ALgt 256;
BA_ "GenSigStartValue" SG_ 2650228734 Obj5VLat 512;
BA_ "GenSigStartValue" SG_ 2650228734 Obj5VLgt 2048;
BA_ "GenSigStartValue" SG_ 2650228734 Obj5DstLat 4096;
BA_ "GenSigStartValue" SG_ 2650228478 Obj4ALgt 256;
BA_ "GenSigStartValue" SG_ 2650228478 Obj4VLat 512;
BA_ "GenSigStartValue" SG_ 2650228478 Obj4VLgt 2048;
BA_ "GenSigStartValue" SG_ 2650228478 Obj4DstLat 4096;
BA_ "GenSigStartValue" SG_ 2650228222 Obj3ALgt 256;
BA_ "GenSigStartValue" SG_ 2650228222 Obj3VLat 512;
BA_ "GenSigStartValue" SG_ 2650228222 Obj3VLgt 2048;
BA_ "GenSigStartValue" SG_ 2650228222 Obj3DstLat 4096;
BA_ "GenSigStartValue" SG_ 2650227966 Obj2ALgt 256;
BA_ "GenSigStartValue" SG_ 2650227966 Obj2VLat 512;
BA_ "GenSigStartValue" SG_ 2650227966 Obj2VLgt 2048;
BA_ "GenSigStartValue" SG_ 2650227966 Obj2DstLat 4096;
BA_ "GenSigStartValue" SG_ 2650227710 Obj1ALgt 256;
BA_ "GenSigStartValue" SG_ 2650227710 Obj1VLat 512;
BA_ "GenSigStartValue" SG_ 2650227710 Obj1VLgt 2048;
BA_ "GenSigStartValue" SG_ 2650227710 Obj1DstLat 4096;
VAL_ 2650227454 AebSt 15 "NA" 14 "Error indication" 7 "Emergency braking active" 6 "Warning with braking active" 5 "Warning active" 4 "Driver overrides system" 3 "Ready and activated" 2 "Deactivated by driver" 1 "Temporarily NA" 0 "Not ready" ;
